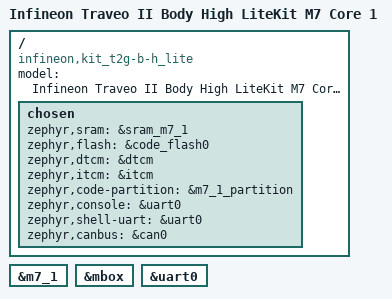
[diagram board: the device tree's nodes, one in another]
/*
 * Copyright (c) 2026 Infineon Technologies AG
 * SPDX-License-Identifier: Apache-2.0
 */

/dts-v1/;
#include "kit_t2g-b-h_lite_common.dtsi"
#include <arm/infineon/cat1c/traveo2-8m/cyt4bf_m7.dtsi>

/ {

	model = "Infineon Traveo II Body High LiteKit M7 Core 1";
	compatible = "infineon,kit_t2g-b-h_lite", "infineon,cyt4bf8cds";

	chosen {
		zephyr,sram = &sram_m7_1;
		zephyr,flash = &code_flash0;
		zephyr,dtcm = &dtcm;
		zephyr,itcm = &itcm;
		zephyr,code-partition = &m7_1_partition;
		zephyr,console = &uart0;
		zephyr,shell-uart = &uart0;
		zephyr,canbus = &can0;
	};
};

&m7_1 {
	status = "okay";
};

&mbox {
	status = "okay";
};

&uart0 {
	status = "okay";
};

